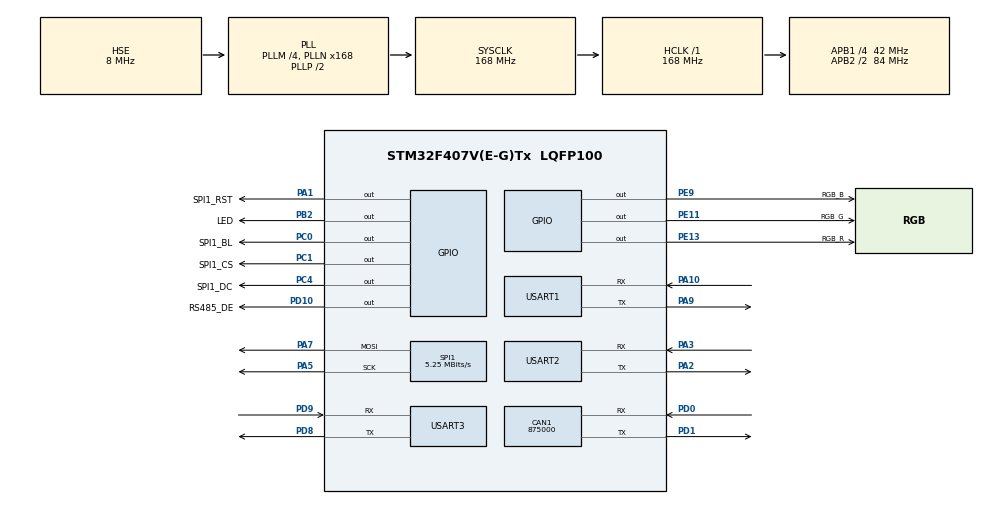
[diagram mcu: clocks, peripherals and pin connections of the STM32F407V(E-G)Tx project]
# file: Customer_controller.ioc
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CAN1.CalculateBaudRate=875000
CAN1.CalculateTimeBit=1142
CAN1.CalculateTimeQuantum=380.95238095238096
Dma.Request0=USART1_RX
Dma.Request1=USART1_TX
Dma.Request2=USART2_RX
Dma.Request3=USART2_TX
Dma.Request4=USART3_RX
Dma.Request5=USART3_TX
Dma.USART1_RX.0.Direction=DMA_PERIPH_TO_MEMORY
Dma.USART1_RX.0.FIFOMode=DMA_FIFOMODE_DISABLE
Dma.USART1_RX.0.Instance=DMA2_Stream2
Dma.USART1_RX.0.MemDataAlignment=DMA_MDATAALIGN_BYTE
Dma.USART1_RX.0.MemInc=DMA_MINC_ENABLE
Dma.USART1_RX.0.Mode=DMA_NORMAL
Dma.USART1_RX.0.PeriphDataAlignment=DMA_PDATAALIGN_BYTE
Dma.USART1_RX.0.PeriphInc=DMA_PINC_DISABLE
Dma.USART1_RX.0.Priority=DMA_PRIORITY_LOW
Dma.USART1_TX.1.Direction=DMA_MEMORY_TO_PERIPH
Dma.USART1_TX.1.FIFOMode=DMA_FIFOMODE_DISABLE
Dma.USART1_TX.1.Instance=DMA2_Stream7
Dma.USART1_TX.1.MemDataAlignment=DMA_MDATAALIGN_BYTE
Dma.USART1_TX.1.MemInc=DMA_MINC_ENABLE
Dma.USART1_TX.1.Mode=DMA_NORMAL
Dma.USART1_TX.1.PeriphDataAlignment=DMA_PDATAALIGN_BYTE
Dma.USART1_TX.1.PeriphInc=DMA_PINC_DISABLE
Dma.USART1_TX.1.Priority=DMA_PRIORITY_LOW
Dma.USART2_RX.2.Direction=DMA_PERIPH_TO_MEMORY
Dma.USART2_RX.2.FIFOMode=DMA_FIFOMODE_DISABLE
Dma.USART2_RX.2.Instance=DMA1_Stream5
Dma.USART2_RX.2.MemDataAlignment=DMA_MDATAALIGN_BYTE
Dma.USART2_RX.2.MemInc=DMA_MINC_ENABLE
Dma.USART2_RX.2.Mode=DMA_NORMAL
Dma.USART2_RX.2.PeriphDataAlignment=DMA_PDATAALIGN_BYTE
Dma.USART2_RX.2.PeriphInc=DMA_PINC_DISABLE
Dma.USART2_RX.2.Priority=DMA_PRIORITY_LOW
Dma.USART2_TX.3.Direction=DMA_MEMORY_TO_PERIPH
Dma.USART2_TX.3.FIFOMode=DMA_FIFOMODE_DISABLE
Dma.USART2_TX.3.Instance=DMA1_Stream6
Dma.USART2_TX.3.MemDataAlignment=DMA_MDATAALIGN_BYTE
Dma.USART2_TX.3.MemInc=DMA_MINC_ENABLE
Dma.USART2_TX.3.Mode=DMA_NORMAL
Dma.USART2_TX.3.PeriphDataAlignment=DMA_PDATAALIGN_BYTE
Dma.USART2_TX.3.PeriphInc=DMA_PINC_DISABLE
Dma.USART2_TX.3.Priority=DMA_PRIORITY_LOW
Dma.USART3_RX.4.Direction=DMA_PERIPH_TO_MEMORY
Dma.USART3_RX.4.FIFOMode=DMA_FIFOMODE_DISABLE
Dma.USART3_RX.4.Instance=DMA1_Stream1
Dma.USART3_RX.4.MemDataAlignment=DMA_MDATAALIGN_BYTE
Dma.USART3_RX.4.MemInc=DMA_MINC_ENABLE
Dma.USART3_RX.4.Mode=DMA_NORMAL
Dma.USART3_RX.4.PeriphDataAlignment=DMA_PDATAALIGN_BYTE
Dma.USART3_RX.4.PeriphInc=DMA_PINC_DISABLE
Dma.USART3_RX.4.Priority=DMA_PRIORITY_LOW
Dma.USART3_TX.5.Direction=DMA_MEMORY_TO_PERIPH
Dma.USART3_TX.5.FIFOMode=DMA_FIFOMODE_DISABLE
Dma.USART3_TX.5.Instance=DMA1_Stream3
Dma.USART3_TX.5.MemDataAlignment=DMA_MDATAALIGN_BYTE
Dma.USART3_TX.5.MemInc=DMA_MINC_ENABLE
Dma.USART3_TX.5.Mode=DMA_NORMAL
Dma.USART3_TX.5.PeriphDataAlignment=DMA_PDATAALIGN_BYTE
Dma.USART3_TX.5.PeriphInc=DMA_PINC_DISABLE
Dma.USART3_TX.5.Priority=DMA_PRIORITY_LOW
Mcu.Family=STM32F4
Mcu.Name=STM32F407V(E-G)Tx
Mcu.Package=LQFP100
NVIC.DMA1_Stream1_IRQn=true\:0\:0\:false\:false\:true\:false\:true\:true
NVIC.DMA1_Stream3_IRQn=true\:0\:0\:false\:false\:true\:false\:true\:true
NVIC.DMA1_Stream5_IRQn=true\:0\:0\:false\:false\:true\:false\:true\:true
NVIC.DMA1_Stream6_IRQn=true\:0\:0\:false\:false\:true\:false\:true\:true
NVIC.DMA2_Stream2_IRQn=true\:0\:0\:false\:false\:true\:false\:true\:true
NVIC.DMA2_Stream7_IRQn=true\:0\:0\:false\:false\:true\:false\:true\:true
NVIC.PriorityGroup=NVIC_PRIORITYGROUP_4
PA1.GPIO_Label=SPI1_RST
PA1.Signal=GPIO_Output
PA10.Mode=Asynchronous
PA10.Signal=USART1_RX
PA13.Mode=Serial_Wire
PA13.Signal=SYS_JTMS-SWDIO
PA14.Mode=Serial_Wire
PA14.Signal=SYS_JTCK-SWCLK
PA2.Mode=Asynchronous
PA2.Signal=USART2_TX
PA3.Mode=Asynchronous
PA3.Signal=USART2_RX
PA5.Mode=TX_Only_Simplex_Unidirect_Master
PA5.Signal=SPI1_SCK
PA7.Mode=TX_Only_Simplex_Unidirect_Master
PA7.Signal=SPI1_MOSI
PA9.Mode=Asynchronous
PA9.Signal=USART1_TX
PB2.GPIO_Label=LED
PB2.Signal=GPIO_Output
PC0.GPIO_Label=SPI1_BL
PC0.GPIO_ModeDefaultOutputPP=GPIO_MODE_OUTPUT_PP
PC0.GPIO_PuPd=GPIO_NOPULL
PC0.PinState=GPIO_PIN_RESET
PC0.Signal=GPIO_Output
PC1.GPIO_Label=SPI1_CS
PC1.Signal=GPIO_Output
PC4.GPIO_Label=SPI1_DC
PC4.Signal=GPIO_Output
PD0.Mode=CAN_Activate
PD0.Signal=CAN1_RX
PD1.Mode=CAN_Activate
PD1.Signal=CAN1_TX
PD10.GPIO_Label=RS485_DE
PD10.Signal=GPIO_Output
PD8.Mode=Asynchronous
PD8.Signal=USART3_TX
PD9.Mode=Asynchronous
PD9.Signal=USART3_RX
PE11.GPIO_Label=RGB_G
PE11.GPIO_PuPd=GPIO_NOPULL
PE11.PinState=GPIO_PIN_SET
PE11.Signal=GPIO_Output
PE13.GPIO_Label=RGB_R
PE13.GPIO_PuPd=GPIO_NOPULL
PE13.PinState=GPIO_PIN_SET
PE13.Signal=GPIO_Output
PE9.GPIO_Label=RGB_B
PE9.GPIO_PuPd=GPIO_NOPULL
PE9.PinState=GPIO_PIN_SET
PE9.Signal=GPIO_Output
PH0-OSC_IN.Mode=HSE-External-Oscillator
PH0-OSC_IN.Signal=RCC_OSC_IN
PH1-OSC_OUT.Mode=HSE-External-Oscillator
PH1-OSC_OUT.Signal=RCC_OSC_OUT
ProjectManager.HeapSize=0x200
ProjectManager.StackSize=0x400
ProjectManager.TargetToolchain=MDK-ARM V5.32
RCC.48MHZClocksFreq_Value=84000000
RCC.AHBFreq_Value=168000000
RCC.APB1CLKDivider=RCC_HCLK_DIV4
RCC.APB1Freq_Value=42000000
RCC.APB1TimFreq_Value=84000000
RCC.APB2CLKDivider=RCC_HCLK_DIV2
RCC.APB2Freq_Value=84000000
RCC.APB2TimFreq_Value=168000000
RCC.CortexFreq_Value=168000000
RCC.HCLKFreq_Value=168000000
RCC.HSE_VALUE=8000000
RCC.HSI_VALUE=16000000
RCC.LSE_VALUE=32768
RCC.PLLM=4
RCC.PLLN=168
RCC.PLLSourceVirtual=RCC_PLLSOURCE_HSE
RCC.SYSCLKFreq_VALUE=168000000
RCC.SYSCLKSource=RCC_SYSCLKSOURCE_PLLCLK
RCC.VCOOutputFreq_Value=336000000
SPI1.BaudRatePrescaler=SPI_BAUDRATEPRESCALER_16
SPI1.CalculateBaudRate=5.25 MBits/s
SPI1.Direction=SPI_DIRECTION_2LINES
SPI1.Mode=SPI_MODE_MASTER
SPI1.VirtualType=VM_MASTER
USART1.VirtualMode=VM_ASYNC
USART2.VirtualMode=VM_ASYNC
USART3.VirtualMode=VM_ASYNC
board=custom

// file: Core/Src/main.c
/* USER CODE BEGIN Header */
/**
  ******************************************************************************
  * @file           : main.c
  * @brief          : Main program body
  ******************************************************************************
  * @attention
  *
  * Copyright (c) 2024 STMicroelectronics.
  * All rights reserved.
  *
  * This software is licensed under terms that can be found in the LICENSE file
  * in the root directory of this software component.
  * If no LICENSE file comes with this software, it is provided AS-IS.
  *
  ******************************************************************************
  */
/* USER CODE END Header */
#include "main.h"
#include "can.h"
#include "dma.h"
#include "spi.h"
#include "usart.h"
#include "gpio.h"

/* USER CODE BEGIN Includes */

#include "st7735.h"
#include "fonts.h"
/* USER CODE END Includes */

void SystemClock_Config(void);

int main(void)
{

  /* MCU Configuration--------------------------------------------------------*/

  /* Reset of all peripherals, Initializes the Flash interface and the Systick. */
  HAL_Init();

  /* Configure the system clock */
  SystemClock_Config();

  /* Initialize all configured peripherals */
  MX_GPIO_Init();
  MX_DMA_Init();
  MX_SPI1_Init();
  MX_USART1_UART_Init();
  MX_USART2_UART_Init();
  MX_USART3_UART_Init();
  MX_CAN1_Init();
  /* USER CODE BEGIN 2 */
//	uint8_t *p[20];
//	*p[0]=1;
//	uint8_t receiveDate[50];
  ST7735_Init();
  /* USER CODE END 2 */

  /* Infinite loop */
  while (1)
  {

    /* USER CODE BEGIN 3 */
//	  	HAL_GPIO_WritePin (SPI1_BL_GPIO_Port ,SPI1_BL_Pin ,GPIO_PIN_RESET );
//		ST7735_FillScreen(ST7735_RED);
//		HAL_Delay(500);
//		ST7735_FillScreen(ST7735_GREEN);
//		HAL_Delay(500);
//		ST7735_FillScreen(ST7735_BLUE);
//		HAL_Delay(500);		//st7735屏幕显示

	  //HAL_GPIO_WritePin (RS485_DE_GPIO_Port ,RS485_DE_Pin ,GPIO_PIN_SET);  //RS485_DE 使能
	  HAL_GPIO_WritePin (RGB_G_GPIO_Port ,RGB_G_Pin ,GPIO_PIN_RESET );
	  HAL_Delay (600);
	  HAL_GPIO_WritePin (RGB_G_GPIO_Port ,RGB_G_Pin ,GPIO_PIN_SET );
	  //HAL_GPIO_WritePin (SPI1_BL_GPIO_Port ,SPI1_BL_Pin ,GPIO_PIN_RESET );  //IPS背光使能
	  //HAL_Delay (500);
	  HAL_UART_Transmit(&huart1, "RoboMaster\r\n", 12, 100);
      HAL_Delay(100);

//	  HAL_UART_Transmit (&huart1,p[0],1,500);
//	   HAL_UART_Transmit (&huart1,(uint8_t *)p,8,500);
//	void HAL_UARTEx_RxEventCallback(UART_HandleTypeDef *huart, uint16_t Size)
//	{
//		HAL_UART_Transmit_DMA (&huart6 ,receiveDate ,Size);
//		HAL_UART_Transmit_DMA(&huart1 ,receiveDate ,Size);

//	    HAL_UARTEx_ReceiveToIdle_DMA  (&huart1 ,receiveDate ,sizeof(receiveDate));
//	    HAL_UARTEx_ReceiveToIdle_DMA  (&huart6 ,receiveDate ,sizeof(receiveDate));
//	}

  }
  /* USER CODE END 3 */
}

void SystemClock_Config(void)
{
  RCC_OscInitTypeDef RCC_OscInitStruct = {0};
  RCC_ClkInitTypeDef RCC_ClkInitStruct = {0};

  /** Configure the main internal regulator output voltage
  */
  __HAL_RCC_PWR_CLK_ENABLE();
  __HAL_PWR_VOLTAGESCALING_CONFIG(PWR_REGULATOR_VOLTAGE_SCALE1);

  /** Initializes the RCC Oscillators according to the specified parameters
  * in the RCC_OscInitTypeDef structure.
  */
  RCC_OscInitStruct.OscillatorType = RCC_OSCILLATORTYPE_HSE;
  RCC_OscInitStruct.HSEState = RCC_HSE_ON;
  RCC_OscInitStruct.PLL.PLLState = RCC_PLL_ON;
  RCC_OscInitStruct.PLL.PLLSource = RCC_PLLSOURCE_HSE;
  RCC_OscInitStruct.PLL.PLLM = 4;
  RCC_OscInitStruct.PLL.PLLN = 168;
  RCC_OscInitStruct.PLL.PLLP = RCC_PLLP_DIV2;
  RCC_OscInitStruct.PLL.PLLQ = 4;
  if (HAL_RCC_OscConfig(&RCC_OscInitStruct) != HAL_OK)
  {
    Error_Handler();
  }

  /** Initializes the CPU, AHB and APB buses clocks
  */
  RCC_ClkInitStruct.ClockType = RCC_CLOCKTYPE_HCLK|RCC_CLOCKTYPE_SYSCLK
                              |RCC_CLOCKTYPE_PCLK1|RCC_CLOCKTYPE_PCLK2;
  RCC_ClkInitStruct.SYSCLKSource = RCC_SYSCLKSOURCE_PLLCLK;
  RCC_ClkInitStruct.AHBCLKDivider = RCC_SYSCLK_DIV1;
  RCC_ClkInitStruct.APB1CLKDivider = RCC_HCLK_DIV4;
  RCC_ClkInitStruct.APB2CLKDivider = RCC_HCLK_DIV2;

  if (HAL_RCC_ClockConfig(&RCC_ClkInitStruct, FLASH_LATENCY_5) != HAL_OK)
  {
    Error_Handler();
  }
}

void Error_Handler(void)
{
  __disable_irq();
  while (1)
  {
  }
}
